# RS1xxxx register map
Vendor: Silicon Lab Inc.; Series: ARMCM4; File version: 1.2
CPU: CM4 r1p0, little endian, MPU, FPU, 6 interrupt priority bits
Registers are 32-bit, read-write, reset 0x0 unless marked. A register's access mark holds for its fields unless they carry their own. Offsets are from the block's base; [hi:lo] are bit positions; lines under a group give offsets from that group; {n}, {i} and the like mark numbered series.

## ULPCLK — This block provides programming support for miscellaneous blocks in the chip. Various features in the chip are enabled using this.
Base 0x24041400
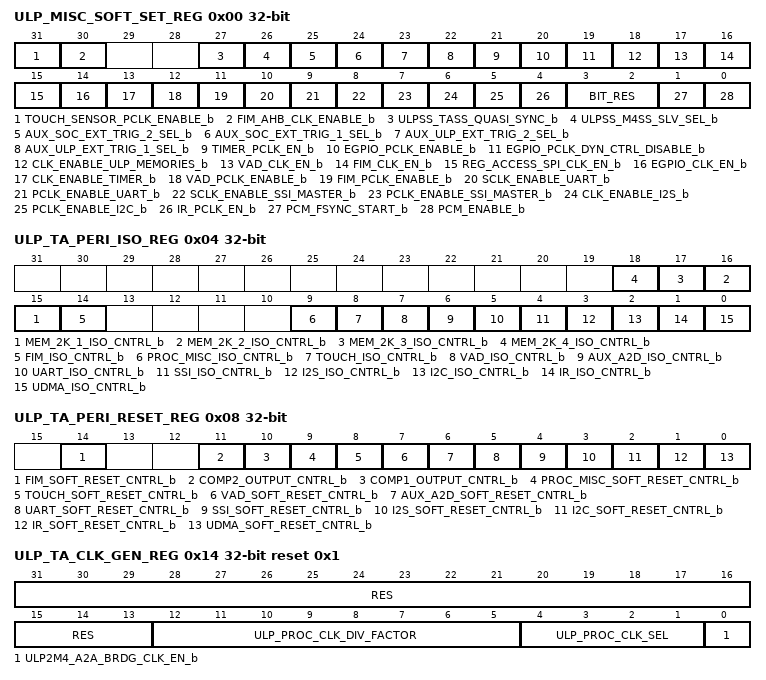
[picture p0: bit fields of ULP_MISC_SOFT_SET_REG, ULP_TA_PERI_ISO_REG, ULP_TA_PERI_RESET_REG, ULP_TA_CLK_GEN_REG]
0x00 ULP_MISC_SOFT_SET_REG — ULP MISC soft register set.
  [31] TOUCH_SENSOR_PCLK_ENABLE_b — Static clock enable for touch APB interface
  [30] FIM_AHB_CLK_ENABLE_b — static clock enable for FIM AHB interface
  [27] ULPSS_TASS_QUASI_SYNC_b — TASS quasi sync
  [26] ULPSS_M4SS_SLV_SEL_b — select slave
  [25] AUX_SOC_EXT_TRIG_2_SEL_b — aux adc dac controller external trigger4 mux select, to choose between soc aux ext trigger2and soc aux ext trigger4.
  [24] AUX_SOC_EXT_TRIG_1_SEL_b — aux adc dac controller external trigger3 mux select, to choose between soc aux ext trigger1and soc aux ext trigger3.
  [23] AUX_ULP_EXT_TRIG_2_SEL_b — aux adc dac controller external trigger2 mux select, to choose between ulp gpio aux ext trigger2 and timer interrupt.
  [22] AUX_ULP_EXT_TRIG_1_SEL_b — aux adc dac controller external trigger2 mux select, to choose between ulp gpio aux ext trigger2 and timer interrupt.
  [21] TIMER_PCLK_EN_b — This bit is used to enable static clock to Timer APB Interface
  [20] EGPIO_PCLK_ENABLE_b — This bit is used to enable static clock to egpio APB interface
  [19] EGPIO_PCLK_DYN_CTRL_DISABLE_b — This bit is used to disable dynamic clock gating on APB clock to egpio
  [18] CLK_ENABLE_ULP_MEMORIES_b — This bit is used to enable clock to memories,if this bit is zero then clock will be available only when the request from the module is present else bit is set(1)then clock is enabled.
  [17] VAD_CLK_EN_b — This bit is used to enable clock to vad module,if this bit is zero then clock will be gated,else bit is one then clock is enabled.
  [16] FIM_CLK_EN_b — This bit is used to enable clock to FIM module,if this bit is zero then clock will be gated,else bit is one then clock is enabled.
  [15] REG_ACCESS_SPI_CLK_EN_b — This bit is used to enable clock to register access spi,if this bit is zero then clock will be available only when the request from the module is present else bit is set(1)then clock is enabled.
  [14] EGPIO_CLK_EN_b — This bit is used to enable clock to gpio,if this bit is zero then clock will be available only when the request from the module is present else bit is set(1)then clock is enabled.
  [13] CLK_ENABLE_TIMER_b — This bit is used to enable clock to Timer,if this bit is zero then clock will be available only when the request from the module is present else bit is set(1)then clock is enabled.
  [12] VAD_PCLK_ENABLE_b — This bit is used to enable clock to FIM reg file,if this bit is zero then clock will be available only when the request from the module is present else bit is set(1)then clock is enabled.
  [11] FIM_PCLK_ENABLE_b — This bit is used to enable clock to FIM reg file,if this bit is zero then clock will be available only when the request from the module is present else bit is set(1)then clock is enabled.
  [10] SCLK_ENABLE_UART_b — This bit is used to enable asynchronous serial clock to UART4,if bit is zero clock will be available only when the request from the module is present.else bit is one then clock is enabled.
  [9] PCLK_ENABLE_UART_b — This bit is used to enable peripheral bus clock to UART4,if bit zero then clock will be available only when the request from the module is present or a transaction is pending on the APB bus,else bit is one then clock is enabled.
  [8] SCLK_ENABLE_SSI_MASTER_b — This bit is used to enable clock serial clock to SSI master,if bit is zero clock will be available only when the request from the module is present.else bit is one then clock is enabled.
  [7] PCLK_ENABLE_SSI_MASTER_b — This bit is used to enable APB bus clock to SSI master,if bit is zero clock will be available only when the request from the module is present.else bit is one then clock is enabled.
  [6] CLK_ENABLE_I2S_b — This bit is used to enable clock to I2S module if bit is set(1)then clock is enabled is bit is zero then clock disabled.
  [5] PCLK_ENABLE_I2C_b — This bit is used as Static enable for APB clock to I2C module,if bit is zero then clock is disabled else bit is one then clock is enabled.
  [4] IR_PCLK_EN_b — Static clock enable for IR APB Interface
  [3:2] BIT_RES — Used in pcm
  [1] PCM_FSYNC_START_b — Used in pcm
  [0] PCM_ENABLE_b — Used in pcm
0x04 ULP_TA_PERI_ISO_REG — ULP TA isolation register.
  [n+14] MEM_2K_{n}_ISO_CNTRL_b (n=1..4) — 2k SRAM memory isolation enable ,if bit is set(1) then enable else bit is zero then disable.
  [14] FIM_ISO_CNTRL_b — FIM module isolation enable ,if bit is set(1) then enable else bit is zero then disable.
  [9] PROC_MISC_ISO_CNTRL_b — mis top(TOT, semaphore, interrupt cntrl, Timer) module isolation enable ,if bit is set(1) then enable else bit is zero then disable.
  [8] TOUCH_ISO_CNTRL_b — CAP sensor module isolation enable,if bit is set(1) then enable else bit is zero then disable.
  [7] VAD_ISO_CNTRL_b — VAD module isolation enable,if bit is set(1) then enable else bit is zero then disable.
  [6] AUX_A2D_ISO_CNTRL_b — AUX a2d module isolation enable,if bit is set(1) then enable else bit is zero then disable.
  [5] UART_ISO_CNTRL_b — UART module isolation enable,if bit is set(1) then enable else bit is zero then disable.
  [4] SSI_ISO_CNTRL_b — SSI module isolation enable ,if bit is set(1) then enable else bit is zero then disable.
  [3] I2S_ISO_CNTRL_b — I2S module isolation enable,if bit is set(1) then enable else bit is zero then disable.
  [2] I2C_ISO_CNTRL_b — I2C module isolation enable,if bit is set(1) then enable else bit is zero then disable.
  [1] IR_ISO_CNTRL_b — IR module isolation enable,if bit is set(1) then enable else bit is zero then disable.
  [0] UDMA_ISO_CNTRL_b — UDMA module isolation enable,if bit is set(1) then enable else bit is zero then disable.
0x08 ULP_TA_PERI_RESET_REG — ULP TA peri reset register.
  [14] FIM_SOFT_RESET_CNTRL_b — FIM module soft reset enable,if bit is set(1) then out of soft reset else bit is zero then in reset
  [11] COMP2_OUTPUT_CNTRL_b — This is ULP comparator2 interrupt unmasking signal. 0 means comparator2 interrupt is masked and 1 means unmasking. It is masked at power-on time.
  [10] COMP1_OUTPUT_CNTRL_b — This is ULP comparator1 interrupt unmasking signal. 0 means comparator1 interrupt is masked and 1 means unmasking. It is masked at power-on time.
  [9] PROC_MISC_SOFT_RESET_CNTRL_b — mis top(TOT, semaphore, interrupt control, Timer) module soft reset enable,if bit is set(1) then out of soft reset else bit is zero then in reset
  [8] TOUCH_SOFT_RESET_CNTRL_b — CAP Sensor module soft reset enable,if bit is set(1) then out of soft reset else bit is zero then in reset.
  [7] VAD_SOFT_RESET_CNTRL_b — VAD module soft reset enable,if bit is set(1) then out of soft reset else bit is zero then in reset.
  [6] AUX_A2D_SOFT_RESET_CNTRL_b — AUX a2d module soft reset enable,if bit is set(1) then out of soft reset else bit is zero then in reset.
  [5] UART_SOFT_RESET_CNTRL_b — UART module soft reset enable ,if bit is set(1) then out of soft reset else bit is zero then in reset.
  [4] SSI_SOFT_RESET_CNTRL_b — SSI module soft reset enable ,if bit is set(1) then out of soft reset else bit is zero then in reset.
  [3] I2S_SOFT_RESET_CNTRL_b — I2S module soft reset enable ,if bit is set(1) then out of soft reset else bit is zero then in reset.
  [2] I2C_SOFT_RESET_CNTRL_b — I2C module soft reset enable ,if bit is set(1) then out of soft reset else bit is zero then in reset.
  [1] IR_SOFT_RESET_CNTRL_b — IR module soft reset enable,if bit is set(1) then out of soft reset else bit is zero then in reset.
  [0] UDMA_SOFT_RESET_CNTRL_b — UDMA module soft reset enable,if bit is set(1) then out of soft reset else bit is zero then in reset.
0x14 ULP_TA_CLK_GEN_REG reset 0x1 — ULP TA clock generation register.
  [31:13] RES — reserved1
  [12:5] ULP_PROC_CLK_DIV_FACTOR — ulp bus clock division factor
  [4:1] ULP_PROC_CLK_SEL — ulp bus clock select.
  [0] ULP2M4_A2A_BRDG_CLK_EN_b — Clock enable for ULP-M4SS AHB-AHB bridge,if bit is set(1) then enable else bit is zero then in disable
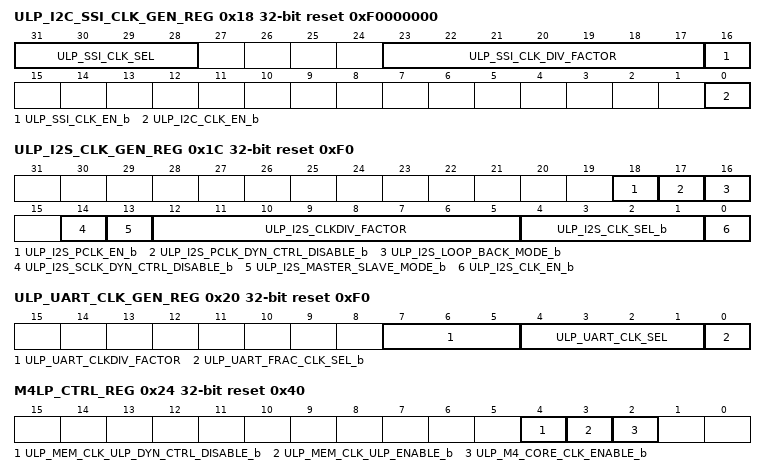
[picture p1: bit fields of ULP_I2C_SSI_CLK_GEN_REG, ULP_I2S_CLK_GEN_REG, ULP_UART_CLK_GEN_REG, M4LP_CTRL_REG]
0x18 ULP_I2C_SSI_CLK_GEN_REG reset 0xF0000000 — ULP I2C SSI clock generation register.
  [31:28] ULP_SSI_CLK_SEL — Ulp ssi clock select.
  [23:17] ULP_SSI_CLK_DIV_FACTOR — ssi clk enable if set(1) then enable else bit is zero then disable
  [16] ULP_SSI_CLK_EN_b — ssi clk enable if set(1) then enable else bit is zero then disable
  [0] ULP_I2C_CLK_EN_b — ulp i2c clock enable,if bit is set(1) then enable else bit is zero then in disable
0x1C ULP_I2S_CLK_GEN_REG reset 0xF0 — ULP I2S clock generation register.
  [18] ULP_I2S_PCLK_EN_b — Static clock enable for APB clock in I2S
  [17] ULP_I2S_PCLK_DYN_CTRL_DISABLE_b — Disable dynamic clock gating of APB clock in I2S
  [16] ULP_I2S_LOOP_BACK_MODE_b — Enables loop back mode in I2S.
  [14] ULP_I2S_SCLK_DYN_CTRL_DISABLE_b — Disable dynamic clock gating of System clock in I2S
  [13] ULP_I2S_MASTER_SLAVE_MODE_b — i2s master slave mode decide field.
  [12:5] ULP_I2S_CLKDIV_FACTOR — ulp i2s clock division factor.
  [4:1] ULP_I2S_CLK_SEL_b — ulp i2s clock select.
  [0] ULP_I2S_CLK_EN_b — ulp i2s clk enable,if bit is set(1) then enable else bit is zero then in disable
0x20 ULP_UART_CLK_GEN_REG reset 0xF0 — ulp uart clock generation register.
  [7:5] ULP_UART_CLKDIV_FACTOR — ulp uart clock division factor
  [4:1] ULP_UART_CLK_SEL — ulp uart clock select.
  [0] ULP_UART_FRAC_CLK_SEL_b — ulp uart clk selection,if bit is set(1) then fractional divider output is selected else swallow divider output is selected
0x24 M4LP_CTRL_REG reset 0x40 — m4 ulp control register
  [4] ULP_MEM_CLK_ULP_DYN_CTRL_DISABLE_b — Disable the dynamic clock gating for M4 memories in ULP mode,if bit is set(1) then dynamic control disabled else dynamic control enabled.
  [3] ULP_MEM_CLK_ULP_ENABLE_b — Static clock enable for M4 memories in ULP mode,if bit is set(1) then clock enable else dynamic control
  [2] ULP_M4_CORE_CLK_ENABLE_b — Static clock enable m4 core in ULP mode,if bit is set(1) then clock enable else clock is disable
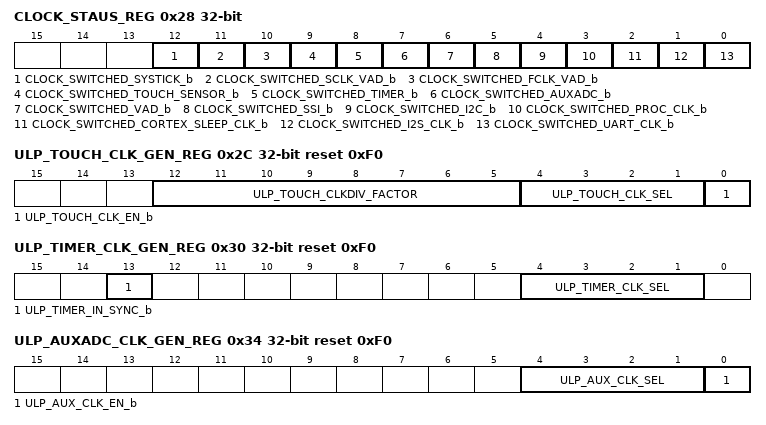
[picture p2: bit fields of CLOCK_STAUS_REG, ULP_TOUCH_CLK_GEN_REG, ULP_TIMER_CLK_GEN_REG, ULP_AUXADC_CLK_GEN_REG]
0x28 CLOCK_STAUS_REG — read clock status register
  [12] CLOCK_SWITCHED_SYSTICK_b ro — Status of clock mux for systick clock,if bit is set(1) then clock is switched,else bit is zero then clock not switched.
  [11] CLOCK_SWITCHED_SCLK_VAD_b ro — Status of clock mux for vad slow clock,if bit is set(1) then clock is switched,else bit is zero then clock not switched.
  [10] CLOCK_SWITCHED_FCLK_VAD_b ro — Status of clock mux for vad fast clock,if bit is set(1) then clock is switched,else bit is zero then clock not switched.
  [9] CLOCK_SWITCHED_TOUCH_SENSOR_b ro — Status of clock mux for touch sensor,if bit is set(1) then clock is switched,else bit is zero then clock not switched.
  [8] CLOCK_SWITCHED_TIMER_b ro — Status of clock mux for async timers,if bit is set(1) then clock is switched,else bit is zero then clock not switched.
  [7] CLOCK_SWITCHED_AUXADC_b ro — Status of clock mux for aux adc dac clock,if bit is set(1) then clock is switched,else bit is zero then clock not switched.
  [6] CLOCK_SWITCHED_VAD_b ro — Status of clock mux for vad,if bit is set(1) then clock is switched,else bit is zero then clock not switched.
  [5] CLOCK_SWITCHED_SSI_b ro — Status of clock mux for ssi,if bit is set(1) then clock is switched,else bit is zero then clock not switched.
  [4] CLOCK_SWITCHED_I2C_b ro — Status of clock mux for i2c,if bit is set(1) then clock is switched,else bit is zero then clock not switched.
  [3] CLOCK_SWITCHED_PROC_CLK_b ro — Status of clock mux for pclk,if bit is set(1) then clock is switched,else bit is zero then clock not switched.
  [2] CLOCK_SWITCHED_CORTEX_SLEEP_CLK_b ro — Status of clock mux for m4 sleep clk,if bit is set(1) then clock is switched,else bit is zero then clock not switched.
  [1] CLOCK_SWITCHED_I2S_CLK_b ro — Status of clock mux for i2s,if bit is set(1) then clock is switched,else bit is zero then clock not switched.
  [0] CLOCK_SWITCHED_UART_CLK_b ro — status of clock mux for uart,if bit is set(1) then clock is switched,else bit is zero then clock not switched.
0x2C ULP_TOUCH_CLK_GEN_REG reset 0xF0 — ULP touch clock generation register
  [12:5] ULP_TOUCH_CLKDIV_FACTOR — ulp touch clock division factor.
  [4:1] ULP_TOUCH_CLK_SEL — ulp touch clock select.
  [0] ULP_TOUCH_CLK_EN_b — ulp touch clk enable,if bit is set(1) then enable,else bit is zero then disable.
0x30 ULP_TIMER_CLK_GEN_REG reset 0xF0 — ULP clock generation for timer
  [13] ULP_TIMER_IN_SYNC_b — Ulp timer in synchronous mode to ULPSS pclk
  [4:1] ULP_TIMER_CLK_SEL — ulp timer clock select.
0x34 ULP_AUXADC_CLK_GEN_REG reset 0xF0 — ULP AUX clock generation register
  [4:1] ULP_AUX_CLK_SEL — ulp aux clock select.
  [0] ULP_AUX_CLK_EN_b — ulp aux clk enable,if bit is one then clock enable else bit is zero then clock disable.
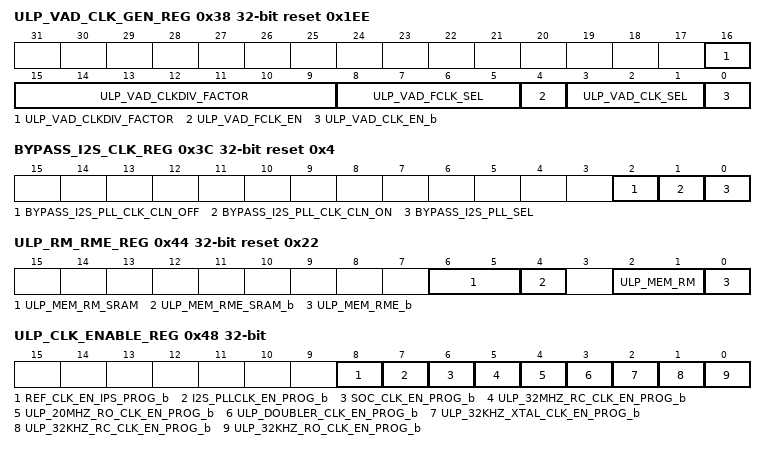
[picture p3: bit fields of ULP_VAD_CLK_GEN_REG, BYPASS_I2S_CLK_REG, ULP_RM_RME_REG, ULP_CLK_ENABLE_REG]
0x38 ULP_VAD_CLK_GEN_REG reset 0x1EE — ULP vad clock generation register
  [16:9] ULP_VAD_CLKDIV_FACTOR — ulp vad clock division factor
  [8:5] ULP_VAD_FCLK_SEL — ulp vad Fast clock select.
  [4] ULP_VAD_FCLK_EN — Enables Fast clock to VAD.
  [3:1] ULP_VAD_CLK_SEL — ulp vad clock select.
  [0] ULP_VAD_CLK_EN_b — ulp vad clk enable ,if bit is one then clock enable else bit is zero then clock disable.
0x3C BYPASS_I2S_CLK_REG reset 0x4 — bypass i2s clock register
  [2] BYPASS_I2S_PLL_CLK_CLN_OFF — I2S PLL Bypass clock cleaner OFF
  [1] BYPASS_I2S_PLL_CLK_CLN_ON — I2S PLL Bypass clock cleaner ON
  [0] BYPASS_I2S_PLL_SEL — Bypass_I2S PLL clock,if bit is one bypass clock is used else bit is zero then I2S Clock is used.
0x44 ULP_RM_RME_REG reset 0x22 — ulp rm rem register
  [6:5] ULP_MEM_RM_SRAM — RM ports for sram memories. This needs to be programmed when the SRAM is not active
  [4] ULP_MEM_RME_SRAM_b — RM enable signal for sram memories. This needs to be programmed when the SRAM is not active.
  [2:1] ULP_MEM_RM — RM ports for memories internal to peripheral. This needs to be programmed when the peripheral memories are not active.
  [0] ULP_MEM_RME_b — RM enable signal for memories internal tp peripherals. This needs to be programmed when the peripheral memories are not active.
0x48 ULP_CLK_ENABLE_REG — ulp clock enable register.
  [8] REF_CLK_EN_IPS_PROG_b — Static Clock enable to iPMU for REF Clock,if bit is one(set) then clock enable else not enable.
  [7] I2S_PLLCLK_EN_PROG_b — Static clock enable to iPMU for I2S-PLL Clock,if bit is one(set) then clock enable else not enable.
  [6] SOC_CLK_EN_PROG_b — Static Clock enable to iPMU for PLL-500 Clock,if bit is one(set) then clock enable else not enable.
  [5] ULP_32MHZ_RC_CLK_EN_PROG_b — Static Clock enable to iPMU for 32MHz RC Clock,if bit is one(set) then clock enable else not enable.
  [4] ULP_20MHZ_RO_CLK_EN_PROG_b — Static Clock enable to iPMU for 20MHz RO clock,if bit is one(set) then clock enable else not enable.
  [3] ULP_DOUBLER_CLK_EN_PROG_b — Static Clock enable to iPMU for Doubler Clock,if bit is one(set) then clock enable else not enable.
  [2] ULP_32KHZ_XTAL_CLK_EN_PROG_b — Static Clock enable to iPMU for 32KHz XTAL Clock,if bit is one(set) then clock enable else not enable.
  [1] ULP_32KHZ_RC_CLK_EN_PROG_b — Static Clock enable to iPMU for 32KHz RC Clock,if bit is one(set) then clock enable else not enable.
  [0] ULP_32KHZ_RO_CLK_EN_PROG_b — Static Clock enable to iPMU for 32KHz RO Clock,if bit is one(set) then clock enable else not enable.
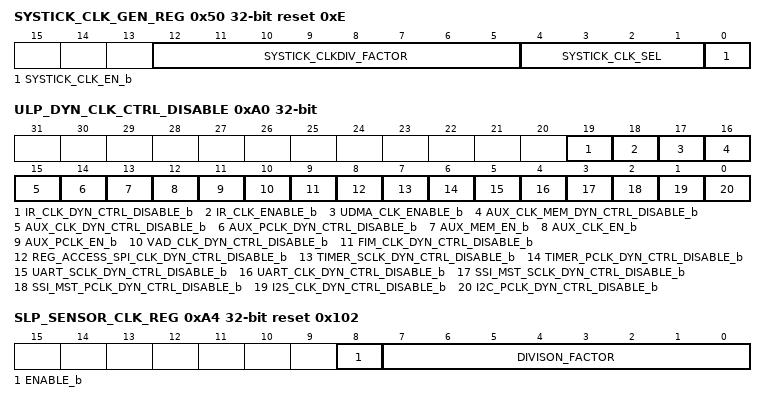
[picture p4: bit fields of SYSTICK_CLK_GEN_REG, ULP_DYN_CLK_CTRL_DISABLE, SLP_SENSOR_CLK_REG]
0x50 SYSTICK_CLK_GEN_REG reset 0xE — sys tick clock generation register.
  [12:5] SYSTICK_CLKDIV_FACTOR — sys tick clock division factor
  [4:1] SYSTICK_CLK_SEL — sys tick clock select
  [0] SYSTICK_CLK_EN_b — sys tick clock enable ,if bit is one(set) then clock enable else not enable.
{0x60+4i} ULP_SOC_GPIO_MODE_REG[{i}] (i=0..15) group — ULP SOC gpio related registers(0-15)
  0x00 ULP_SOC_GPIO_MODE_REG — ulp soc gpio mode register
    [2:0] ULP_SOC_GPIO_MODE_REG — mode bits for soc gpio.
0xA0 ULP_DYN_CLK_CTRL_DISABLE — this register used for ULP dynamic clock control disable.
  [19] IR_CLK_DYN_CTRL_DISABLE_b — Dynamic clock control disable for ir module ,if bit is one(set) then dynamic control disabled else bit is zero then Dynamic control enabled.
  [18] IR_CLK_ENABLE_b — Static Enable for IR.
  [17] UDMA_CLK_ENABLE_b — Static Enable for UDMA.
  [16] AUX_CLK_MEM_DYN_CTRL_DISABLE_b — Dynamic clock control disable for aux adc mem,if bit is one(set) then dynamic control disabled else bit is zero then Dynamic control enabled.
  [15] AUX_CLK_DYN_CTRL_DISABLE_b — Dynamic clock control disable for aux adc module,if bit is one(set) then dynamic control disabled else bit is zero then Dynamic control enabled.
  [14] AUX_PCLK_DYN_CTRL_DISABLE_b — Dynamic clock control disable for aux adc module,if bit is one(set) then dynamic control disabled else bit is zero then Dynamic control enabled.
  [13] AUX_MEM_EN_b — Static Enable for Aux adc mem.
  [12] AUX_CLK_EN_b — Static Enable for Aux adc clk.
  [11] AUX_PCLK_EN_b — Static Enable for Aux adc pclk.
  [10] VAD_CLK_DYN_CTRL_DISABLE_b — Dynamic clock control disable for vad module,if bit is one(set) then dynamic control disabled else bit is zero then Dynamic control enabled.
  [9] FIM_CLK_DYN_CTRL_DISABLE_b — Dynamic clock control disable for fim module,if bit is one(set) then dynamic control disabled else bit is zero then Dynamic control enabled.
  [8] REG_ACCESS_SPI_CLK_DYN_CTRL_DISABLE_b — Dynamic clock control disable for reg access spi module,if bit is one(set) then dynamic control disabled else bit is zero then Dynamic control enabled.
  [7] TIMER_SCLK_DYN_CTRL_DISABLE_b — Dynamic clock control disable for timer sclk module,if bit is one(set) then dynamic control disabled else bit is zero then Dynamic control enabled.
  [6] TIMER_PCLK_DYN_CTRL_DISABLE_b — Dynamic clock control disable for timer pclk module,if bit is one(set) then dynamic control disabled else bit is zero then Dynamic control enabled.
  [5] UART_SCLK_DYN_CTRL_DISABLE_b — Dynamic clock control disable for uart module,if bit is one(set) then dynamic control disabled else bit is zero then Dynamic control enabled.
  [4] UART_CLK_DYN_CTRL_DISABLE_b — Dynamic clock control disable for pclk uart module ,if bit is one(set) then dynamic control disabled else bit is zero then Dynamic control enabled.
  [3] SSI_MST_SCLK_DYN_CTRL_DISABLE_b — Dynamic clock control disable for ssi module,if bit is one(set) then dynamic control disabled else bit is zero then Dynamic control enabled.
  [2] SSI_MST_PCLK_DYN_CTRL_DISABLE_b — Dynamic clock control disable for pclk ssi module,if bit is one(set) then dynamic control disabled else bit is zero then Dynamic control enabled.
  [1] I2S_CLK_DYN_CTRL_DISABLE_b — Dynamic clock control disable for i2s module,if bit is one(set) then dynamic control disabled else bit is zero then Dynamic control enabled.
  [0] I2C_PCLK_DYN_CTRL_DISABLE_b — Dynamic clock control disable for APB interface in i2c module,if bit is one(set) then dynamic control disabled else bit is zero then Dynamic control enabled.
0xA4 SLP_SENSOR_CLK_REG reset 0x102 — this register used for SLP sensor clock register.
  [8] ENABLE_b — Enable for APB clock to SLPSS
  [7:0] DIVISON_FACTOR — Division factor for apb interface clock to sleep sensor subsystem.
